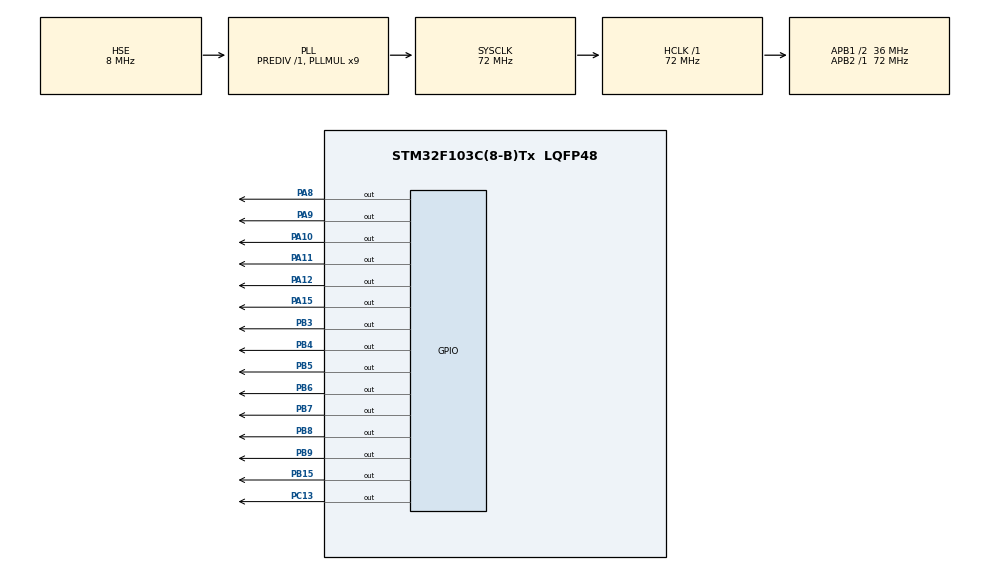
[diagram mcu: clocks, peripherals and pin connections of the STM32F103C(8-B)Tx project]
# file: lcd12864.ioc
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Mcu.Family=STM32F1
Mcu.Name=STM32F103C(8-B)Tx
Mcu.Package=LQFP48
NVIC.PriorityGroup=NVIC_PRIORITYGROUP_4
PA10.GPIO_ModeDefaultOutputPP=GPIO_MODE_OUTPUT_OD
PA10.GPIO_PuPd=GPIO_NOPULL
PA10.GPIO_Speed=GPIO_SPEED_FREQ_LOW
PA10.PinState=GPIO_PIN_SET
PA10.Signal=GPIO_Output
PA11.GPIO_ModeDefaultOutputPP=GPIO_MODE_OUTPUT_OD
PA11.GPIO_PuPd=GPIO_NOPULL
PA11.GPIO_Speed=GPIO_SPEED_FREQ_LOW
PA11.PinState=GPIO_PIN_SET
PA11.Signal=GPIO_Output
PA12.GPIO_ModeDefaultOutputPP=GPIO_MODE_OUTPUT_OD
PA12.GPIO_PuPd=GPIO_NOPULL
PA12.GPIO_Speed=GPIO_SPEED_FREQ_LOW
PA12.PinState=GPIO_PIN_SET
PA12.Signal=GPIO_Output
PA13.Mode=Serial_Wire
PA13.Signal=SYS_JTMS-SWDIO
PA14.Mode=Serial_Wire
PA14.Signal=SYS_JTCK-SWCLK
PA15.GPIO_ModeDefaultOutputPP=GPIO_MODE_OUTPUT_OD
PA15.GPIO_PuPd=GPIO_NOPULL
PA15.GPIO_Speed=GPIO_SPEED_FREQ_LOW
PA15.PinState=GPIO_PIN_SET
PA15.Signal=GPIO_Output
PA8.GPIO_ModeDefaultOutputPP=GPIO_MODE_OUTPUT_PP
PA8.GPIO_PuPd=GPIO_NOPULL
PA8.GPIO_Speed=GPIO_SPEED_FREQ_LOW
PA8.PinState=GPIO_PIN_RESET
PA8.Signal=GPIO_Output
PA9.GPIO_ModeDefaultOutputPP=GPIO_MODE_OUTPUT_PP
PA9.GPIO_PuPd=GPIO_NOPULL
PA9.GPIO_Speed=GPIO_SPEED_FREQ_LOW
PA9.PinState=GPIO_PIN_RESET
PA9.Signal=GPIO_Output
PB15.GPIO_ModeDefaultOutputPP=GPIO_MODE_OUTPUT_PP
PB15.GPIO_PuPd=GPIO_NOPULL
PB15.GPIO_Speed=GPIO_SPEED_FREQ_LOW
PB15.PinState=GPIO_PIN_RESET
PB15.Signal=GPIO_Output
PB3.GPIO_ModeDefaultOutputPP=GPIO_MODE_OUTPUT_OD
PB3.GPIO_PuPd=GPIO_NOPULL
PB3.GPIO_Speed=GPIO_SPEED_FREQ_LOW
PB3.PinState=GPIO_PIN_SET
PB3.Signal=GPIO_Output
PB4.GPIO_ModeDefaultOutputPP=GPIO_MODE_OUTPUT_OD
PB4.GPIO_PuPd=GPIO_NOPULL
PB4.GPIO_Speed=GPIO_SPEED_FREQ_LOW
PB4.PinState=GPIO_PIN_SET
PB4.Signal=GPIO_Output
PB5.GPIO_ModeDefaultOutputPP=GPIO_MODE_OUTPUT_OD
PB5.GPIO_PuPd=GPIO_NOPULL
PB5.GPIO_Speed=GPIO_SPEED_FREQ_LOW
PB5.PinState=GPIO_PIN_SET
PB5.Signal=GPIO_Output
PB6.GPIO_ModeDefaultOutputPP=GPIO_MODE_OUTPUT_OD
PB6.GPIO_PuPd=GPIO_NOPULL
PB6.GPIO_Speed=GPIO_SPEED_FREQ_LOW
PB6.PinState=GPIO_PIN_SET
PB6.Signal=GPIO_Output
PB7.GPIO_ModeDefaultOutputPP=GPIO_MODE_OUTPUT_PP
PB7.GPIO_PuPd=GPIO_NOPULL
PB7.GPIO_Speed=GPIO_SPEED_FREQ_LOW
PB7.PinState=GPIO_PIN_RESET
PB7.Signal=GPIO_Output
PB8.GPIO_ModeDefaultOutputPP=GPIO_MODE_OUTPUT_PP
PB8.GPIO_PuPd=GPIO_NOPULL
PB8.GPIO_Speed=GPIO_SPEED_FREQ_LOW
PB8.PinState=GPIO_PIN_RESET
PB8.Signal=GPIO_Output
PB9.GPIO_ModeDefaultOutputPP=GPIO_MODE_OUTPUT_PP
PB9.GPIO_PuPd=GPIO_NOPULL
PB9.GPIO_Speed=GPIO_SPEED_FREQ_LOW
PB9.PinState=GPIO_PIN_RESET
PB9.Signal=GPIO_Output
PC13-TAMPER-RTC.GPIO_ModeDefaultOutputPP=GPIO_MODE_OUTPUT_OD
PC13-TAMPER-RTC.Signal=GPIO_Output
PC14-OSC32_IN.Mode=LSE-External-Oscillator
PC14-OSC32_IN.Signal=RCC_OSC32_IN
PC15-OSC32_OUT.Mode=LSE-External-Oscillator
PC15-OSC32_OUT.Signal=RCC_OSC32_OUT
PD0-OSC_IN.Mode=HSE-External-Oscillator
PD0-OSC_IN.Signal=RCC_OSC_IN
PD1-OSC_OUT.Mode=HSE-External-Oscillator
PD1-OSC_OUT.Signal=RCC_OSC_OUT
ProjectManager.HeapSize=0x1000
ProjectManager.StackSize=0x1000
ProjectManager.TargetToolchain=MDK-ARM V5
RCC.AHBFreq_Value=72000000
RCC.APB1CLKDivider=RCC_HCLK_DIV2
RCC.APB1Freq_Value=36000000
RCC.APB1TimFreq_Value=72000000
RCC.APB2Freq_Value=72000000
RCC.APB2TimFreq_Value=72000000
RCC.HCLKFreq_Value=72000000
RCC.PLLMUL=RCC_PLL_MUL9
RCC.PLLSourceVirtual=RCC_PLLSOURCE_HSE
RCC.SYSCLKFreq_VALUE=72000000
RCC.SYSCLKSource=RCC_SYSCLKSOURCE_PLLCLK
RCC.USBFreq_Value=72000000
board=custom

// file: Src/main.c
/* USER CODE BEGIN Header */
/**
  ******************************************************************************
  * @file           : main.c
  * @brief          : Main program body
  ******************************************************************************
  * @attention
  *
  * <h2><center>&copy; Copyright (c) 2019 STMicroelectronics.
  * All rights reserved.</center></h2>
  *
  * This software component is licensed by ST under BSD 3-Clause license,
  * the "License"; You may not use this file except in compliance with the
  * License. You may obtain a copy of the License at:
  *                        opensource.org/licenses/BSD-3-Clause
  *
  ******************************************************************************
  */
/* USER CODE END Header */

#include "main.h"

/* USER CODE BEGIN Includes */
#include "lcd_user.h"
/* USER CODE END Includes */

void SystemClock_Config(void);
static void MX_GPIO_Init(void);

int main(void)
{

  /* MCU Configuration--------------------------------------------------------*/

  /* Reset of all peripherals, Initializes the Flash interface and the Systick. */
  HAL_Init();

  /* Configure the system clock */
  SystemClock_Config();

  /* Initialize all configured peripherals */
  MX_GPIO_Init();
  /* USER CODE BEGIN 2 */
	LCDInit();
	LCDPrint(0,"Manufactur",10);
	LCDPrint(1,"ed  By",6);
	LCDPrint(2,"Thermit YE",10);
  /* USER CODE END 2 */

  /* Infinite loop */
  /* USER CODE BEGIN WHILE */
	while (1)
  {
		HAL_GPIO_WritePin(GPIOC,GPIO_PIN_13,GPIO_PIN_SET);
		HAL_Delay(500);

		HAL_GPIO_WritePin(GPIOC,GPIO_PIN_13,GPIO_PIN_RESET);
		HAL_Delay(500);
    /* USER CODE END WHILE */

  }
}

void SystemClock_Config(void)
{
  RCC_OscInitTypeDef RCC_OscInitStruct = {0};
  RCC_ClkInitTypeDef RCC_ClkInitStruct = {0};

  /** Initializes the CPU, AHB and APB busses clocks
  */
  RCC_OscInitStruct.OscillatorType = RCC_OSCILLATORTYPE_HSE;
  RCC_OscInitStruct.HSEState = RCC_HSE_ON;
  RCC_OscInitStruct.HSEPredivValue = RCC_HSE_PREDIV_DIV1;
  RCC_OscInitStruct.HSIState = RCC_HSI_ON;
  RCC_OscInitStruct.PLL.PLLState = RCC_PLL_ON;
  RCC_OscInitStruct.PLL.PLLSource = RCC_PLLSOURCE_HSE;
  RCC_OscInitStruct.PLL.PLLMUL = RCC_PLL_MUL9;
  if (HAL_RCC_OscConfig(&RCC_OscInitStruct) != HAL_OK)
  {
    Error_Handler();
  }
  /** Initializes the CPU, AHB and APB busses clocks
  */
  RCC_ClkInitStruct.ClockType = RCC_CLOCKTYPE_HCLK|RCC_CLOCKTYPE_SYSCLK
                              |RCC_CLOCKTYPE_PCLK1|RCC_CLOCKTYPE_PCLK2;
  RCC_ClkInitStruct.SYSCLKSource = RCC_SYSCLKSOURCE_PLLCLK;
  RCC_ClkInitStruct.AHBCLKDivider = RCC_SYSCLK_DIV1;
  RCC_ClkInitStruct.APB1CLKDivider = RCC_HCLK_DIV2;
  RCC_ClkInitStruct.APB2CLKDivider = RCC_HCLK_DIV1;

  if (HAL_RCC_ClockConfig(&RCC_ClkInitStruct, FLASH_LATENCY_2) != HAL_OK)
  {
    Error_Handler();
  }
}

static void MX_GPIO_Init(void)
{
  GPIO_InitTypeDef GPIO_InitStruct = {0};

  /* GPIO Ports Clock Enable */
  __HAL_RCC_GPIOC_CLK_ENABLE();
  __HAL_RCC_GPIOD_CLK_ENABLE();
  __HAL_RCC_GPIOB_CLK_ENABLE();
  __HAL_RCC_GPIOA_CLK_ENABLE();

  /*Configure GPIO pin Output Level */
  HAL_GPIO_WritePin(GPIOC, GPIO_PIN_13, GPIO_PIN_RESET);

  /*Configure GPIO pin Output Level */
  HAL_GPIO_WritePin(GPIOB, GPIO_PIN_15|GPIO_PIN_7|GPIO_PIN_8|GPIO_PIN_9, GPIO_PIN_RESET);

  /*Configure GPIO pin Output Level */
  HAL_GPIO_WritePin(GPIOA, GPIO_PIN_8|GPIO_PIN_9, GPIO_PIN_RESET);

  /*Configure GPIO pin Output Level */
  HAL_GPIO_WritePin(GPIOA, GPIO_PIN_10|GPIO_PIN_11|GPIO_PIN_12|GPIO_PIN_15, GPIO_PIN_SET);

  /*Configure GPIO pin Output Level */
  HAL_GPIO_WritePin(GPIOB, GPIO_PIN_3|GPIO_PIN_4|GPIO_PIN_5|GPIO_PIN_6, GPIO_PIN_SET);

  /*Configure GPIO pin : PC13 */
  GPIO_InitStruct.Pin = GPIO_PIN_13;
  GPIO_InitStruct.Mode = GPIO_MODE_OUTPUT_OD;
  GPIO_InitStruct.Pull = GPIO_NOPULL;
  GPIO_InitStruct.Speed = GPIO_SPEED_FREQ_LOW;
  HAL_GPIO_Init(GPIOC, &GPIO_InitStruct);

  /*Configure GPIO pins : PB15 PB7 PB8 PB9 */
  GPIO_InitStruct.Pin = GPIO_PIN_15|GPIO_PIN_7|GPIO_PIN_8|GPIO_PIN_9;
  GPIO_InitStruct.Mode = GPIO_MODE_OUTPUT_PP;
  GPIO_InitStruct.Pull = GPIO_NOPULL;
  GPIO_InitStruct.Speed = GPIO_SPEED_FREQ_LOW;
  HAL_GPIO_Init(GPIOB, &GPIO_InitStruct);

  /*Configure GPIO pins : PA8 PA9 */
  GPIO_InitStruct.Pin = GPIO_PIN_8|GPIO_PIN_9;
  GPIO_InitStruct.Mode = GPIO_MODE_OUTPUT_PP;
  GPIO_InitStruct.Pull = GPIO_NOPULL;
  GPIO_InitStruct.Speed = GPIO_SPEED_FREQ_LOW;
  HAL_GPIO_Init(GPIOA, &GPIO_InitStruct);

  /*Configure GPIO pins : PA10 PA11 PA12 PA15 */
  GPIO_InitStruct.Pin = GPIO_PIN_10|GPIO_PIN_11|GPIO_PIN_12|GPIO_PIN_15;
  GPIO_InitStruct.Mode = GPIO_MODE_OUTPUT_OD;
  GPIO_InitStruct.Pull = GPIO_NOPULL;
  GPIO_InitStruct.Speed = GPIO_SPEED_FREQ_LOW;
  HAL_GPIO_Init(GPIOA, &GPIO_InitStruct);

  /*Configure GPIO pins : PB3 PB4 PB5 PB6 */
  GPIO_InitStruct.Pin = GPIO_PIN_3|GPIO_PIN_4|GPIO_PIN_5|GPIO_PIN_6;
  GPIO_InitStruct.Mode = GPIO_MODE_OUTPUT_OD;
  GPIO_InitStruct.Pull = GPIO_NOPULL;
  GPIO_InitStruct.Speed = GPIO_SPEED_FREQ_LOW;
  HAL_GPIO_Init(GPIOB, &GPIO_InitStruct);

}

void Error_Handler(void)
{
}

/************************ (C) COPYRIGHT STMicroelectronics *****END OF FILE****/
